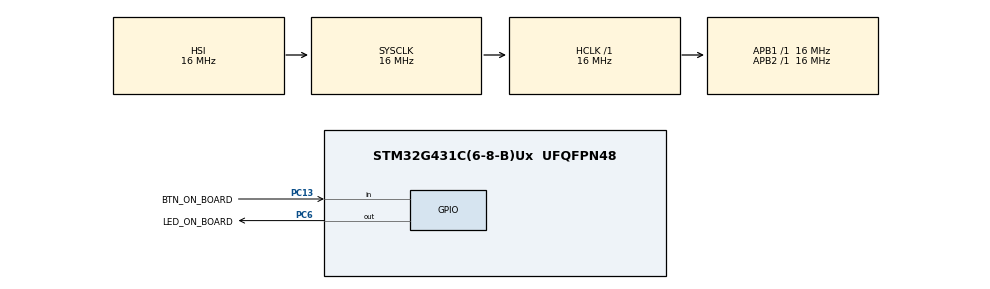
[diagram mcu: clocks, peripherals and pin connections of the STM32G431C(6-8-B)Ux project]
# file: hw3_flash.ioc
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Mcu.Family=STM32G4
Mcu.Name=STM32G431C(6-8-B)Ux
Mcu.Package=UFQFPN48
NVIC.PriorityGroup=NVIC_PRIORITYGROUP_4
PA13.Mode=Serial_Wire
PA13.Signal=SYS_JTMS-SWDIO
PA14.Mode=Serial_Wire
PA14.Signal=SYS_JTCK-SWCLK
PC13.GPIO_Label=BTN_ON_BOARD
PC13.GPIO_PuPd=GPIO_PULLDOWN
PC13.Signal=GPIO_Input
PC14-OSC32_IN.Mode=LSE-External-Oscillator
PC14-OSC32_IN.Signal=RCC_OSC32_IN
PC15-OSC32_OUT.Mode=LSE-External-Oscillator
PC15-OSC32_OUT.Signal=RCC_OSC32_OUT
PC6.GPIO_Label=LED_ON_BOARD
PC6.Signal=GPIO_Output
PF0-OSC_IN.Mode=HSE-External-Oscillator
PF0-OSC_IN.Signal=RCC_OSC_IN
PF1-OSC_OUT.Mode=HSE-External-Oscillator
PF1-OSC_OUT.Signal=RCC_OSC_OUT
ProjectManager.HeapSize=0x200
ProjectManager.StackSize=0x400
ProjectManager.TargetToolchain=STM32CubeIDE
RCC.AHBFreq_Value=16000000
RCC.APB1Freq_Value=16000000
RCC.APB1TimFreq_Value=16000000
RCC.APB2Freq_Value=16000000
RCC.APB2TimFreq_Value=16000000
RCC.CortexFreq_Value=16000000
RCC.EXTERNAL_CLOCK_VALUE=12288000
RCC.HCLKFreq_Value=16000000
RCC.HSE_VALUE=8000000
RCC.HSI48_VALUE=48000000
RCC.HSI_VALUE=16000000
RCC.SYSCLKFreq_VALUE=16000000
RCC.USBFreq_Value=64000000
RCC.VCOOutputFreq_Value=128000000
VP_SYS_VS_DBSignals.Mode=DisableDeadBatterySignals
board=custom

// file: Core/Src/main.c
/* USER CODE BEGIN Header */
/**
  ******************************************************************************
  * @file           : main.c
  * @brief          : Main program body
  ******************************************************************************
  * @attention
  *
  * Copyright (c) 2025 STMicroelectronics.
  * All rights reserved.
  *
  * This software is licensed under terms that can be found in the LICENSE file
  * in the root directory of this software component.
  * If no LICENSE file comes with this software, it is provided AS-IS.
  *
  ******************************************************************************
  */
/* USER CODE END Header */
#include "main.h"

/* USER CODE BEGIN Includes */
#include <string.h>
/* USER CODE END Includes */

/* USER CODE BEGIN PTD */
typedef struct {
    char      msg[50];
    float     num1;
    uint32_t  num2;
    uint16_t  num3;
    uint64_t  num4;
} test_t;
typedef uint64_t data_NVRAM_t;

/* USER CODE END PTD */

/* USER CODE BEGIN PD */
#define FLASH_USER_PAGE         (9U)
#define FLASH_USER_NB_PAGES     (1U)
#define FLASH_USER_START_ADDR   (FLASH_BASE + FLASH_PAGE_SIZE * FLASH_USER_PAGE)
#define FLASH_USER_END_ADDR     (FLASH_USER_START_ADDR + FLASH_USER_NB_PAGES * FLASH_PAGE_SIZE - 1)

/* USER CODE END PD */

void SystemClock_Config(void);
static void MX_GPIO_Init(void);

int main(void)
{

  /* MCU Configuration--------------------------------------------------------*/

  /* Reset of all peripherals, Initializes the Flash interface and the Systick. */
  HAL_Init();

  /* Configure the system clock */
  SystemClock_Config();

  /* Initialize all configured peripherals */
  MX_GPIO_Init();

  /* Infinite loop */
  /* USER CODE BEGIN WHILE */

  uint8_t WriteFlag = 0;

  union NVRAM_PAGE {
            test_t test;
            data_NVRAM_t data[FLASH_PAGE_SIZE / sizeof(data_NVRAM_t)];
          } DevNVRAM_Page;

  memset(DevNVRAM_Page.data, 0, sizeof(DevNVRAM_Page.data));
  DevNVRAM_Page.test.num1 = 3.14;
  DevNVRAM_Page.test.num2 = 0xBEEFBEEF;
  DevNVRAM_Page.test.num3 = 0xBABE;
  DevNVRAM_Page.test.num4 = 0xDEADBEEFDEADBEEF;
  strcpy(DevNVRAM_Page.test.msg, "MEMORY TEST MESSAGE");

  while (1)
  {
    if(HAL_GPIO_ReadPin(BTN_ON_BOARD_GPIO_Port, BTN_ON_BOARD_Pin) == GPIO_PIN_SET && !WriteFlag)
    {
      FLASH_EraseInitTypeDef EraseInitStruct;
      uint32_t PageError = 0;
      uint32_t Address = FLASH_USER_START_ADDR;

      if(Address < FLASH_USER_END_ADDR && Address > (FLASH_BASE + FLASH_SIZE - FLASH_PAGE_SIZE))
      {
        while (1)
        {
          HAL_GPIO_TogglePin(LED_ON_BOARD_GPIO_Port, LED_ON_BOARD_Pin);
          HAL_Delay(500);
        }
      }

      HAL_FLASH_Unlock();
      __HAL_FLASH_CLEAR_FLAG(FLASH_FLAG_OPTVERR);

      EraseInitStruct.TypeErase = FLASH_TYPEERASE_PAGES;
      EraseInitStruct.Page      = FLASH_USER_PAGE;
      EraseInitStruct.NbPages   = FLASH_USER_NB_PAGES;

      /*Стиание*/
      if(HAL_FLASHEx_Erase(&EraseInitStruct, &PageError) != HAL_OK)
      {
        while (1)
        {
          HAL_GPIO_TogglePin(LED_ON_BOARD_GPIO_Port, LED_ON_BOARD_Pin);
          HAL_Delay(500);
        }
      }
      /*Запись*/
      for(uint32_t i = 0; Address < FLASH_USER_END_ADDR; i++)//while(Address < FLASH_USER_END_ADDR)
      {
        if (HAL_FLASH_Program(FLASH_TYPEPROGRAM_DOUBLEWORD, Address, DevNVRAM_Page.data[i]) == HAL_OK)
        {
          Address += sizeof(data_NVRAM_t);
        }
        else
        {
          while (1)
          {
            HAL_GPIO_TogglePin(LED_ON_BOARD_GPIO_Port, LED_ON_BOARD_Pin);
            HAL_Delay(500);
          }
        }
      }
      WriteFlag = 1;
      HAL_FLASH_Lock();

      /*Сравнение исходной и записанной*/
      Address = FLASH_USER_START_ADDR;
      uint8_t MemoryError = 0x0;

      for(uint32_t i = 0; Address < FLASH_USER_END_ADDR; i++)
      {
        if (*(data_NVRAM_t *)Address != DevNVRAM_Page.data[i])
        {
          MemoryError++;
        }
        Address += sizeof(data_NVRAM_t);
      }

      if (!MemoryError)
      {
        HAL_GPIO_WritePin(LED_ON_BOARD_GPIO_Port, LED_ON_BOARD_Pin, GPIO_PIN_SET);
      }
      else
      {
        while (1)
        {
          HAL_GPIO_WritePin(LED_ON_BOARD_GPIO_Port, LED_ON_BOARD_Pin, GPIO_PIN_SET);
          HAL_Delay(200);
          HAL_GPIO_WritePin(LED_ON_BOARD_GPIO_Port, LED_ON_BOARD_Pin, GPIO_PIN_RESET);
          HAL_Delay(800);
        }
      }

    }

    /* USER CODE END WHILE */

  }
}

void SystemClock_Config(void)
{
  RCC_OscInitTypeDef RCC_OscInitStruct = {0};
  RCC_ClkInitTypeDef RCC_ClkInitStruct = {0};

  /** Configure the main internal regulator output voltage
  */
  HAL_PWREx_ControlVoltageScaling(PWR_REGULATOR_VOLTAGE_SCALE1);

  /** Initializes the RCC Oscillators according to the specified parameters
  * in the RCC_OscInitTypeDef structure.
  */
  RCC_OscInitStruct.OscillatorType = RCC_OSCILLATORTYPE_HSI;
  RCC_OscInitStruct.HSIState = RCC_HSI_ON;
  RCC_OscInitStruct.HSICalibrationValue = RCC_HSICALIBRATION_DEFAULT;
  RCC_OscInitStruct.PLL.PLLState = RCC_PLL_NONE;
  if (HAL_RCC_OscConfig(&RCC_OscInitStruct) != HAL_OK)
  {
    Error_Handler();
  }

  /** Initializes the CPU, AHB and APB buses clocks
  */
  RCC_ClkInitStruct.ClockType = RCC_CLOCKTYPE_HCLK|RCC_CLOCKTYPE_SYSCLK
                              |RCC_CLOCKTYPE_PCLK1|RCC_CLOCKTYPE_PCLK2;
  RCC_ClkInitStruct.SYSCLKSource = RCC_SYSCLKSOURCE_HSI;
  RCC_ClkInitStruct.AHBCLKDivider = RCC_SYSCLK_DIV1;
  RCC_ClkInitStruct.APB1CLKDivider = RCC_HCLK_DIV1;
  RCC_ClkInitStruct.APB2CLKDivider = RCC_HCLK_DIV1;

  if (HAL_RCC_ClockConfig(&RCC_ClkInitStruct, FLASH_LATENCY_0) != HAL_OK)
  {
    Error_Handler();
  }
}

static void MX_GPIO_Init(void)
{
  GPIO_InitTypeDef GPIO_InitStruct = {0};

  /* GPIO Ports Clock Enable */
  __HAL_RCC_GPIOC_CLK_ENABLE();
  __HAL_RCC_GPIOF_CLK_ENABLE();
  __HAL_RCC_GPIOA_CLK_ENABLE();

  /*Configure GPIO pin Output Level */
  HAL_GPIO_WritePin(LED_ON_BOARD_GPIO_Port, LED_ON_BOARD_Pin, GPIO_PIN_RESET);

  /*Configure GPIO pin : BTN_ON_BOARD_Pin */
  GPIO_InitStruct.Pin = BTN_ON_BOARD_Pin;
  GPIO_InitStruct.Mode = GPIO_MODE_INPUT;
  GPIO_InitStruct.Pull = GPIO_PULLDOWN;
  HAL_GPIO_Init(BTN_ON_BOARD_GPIO_Port, &GPIO_InitStruct);

  /*Configure GPIO pin : LED_ON_BOARD_Pin */
  GPIO_InitStruct.Pin = LED_ON_BOARD_Pin;
  GPIO_InitStruct.Mode = GPIO_MODE_OUTPUT_PP;
  GPIO_InitStruct.Pull = GPIO_NOPULL;
  GPIO_InitStruct.Speed = GPIO_SPEED_FREQ_LOW;
  HAL_GPIO_Init(LED_ON_BOARD_GPIO_Port, &GPIO_InitStruct);

}

void Error_Handler(void)
{
  __disable_irq();
  while (1)
  {
  }
}
